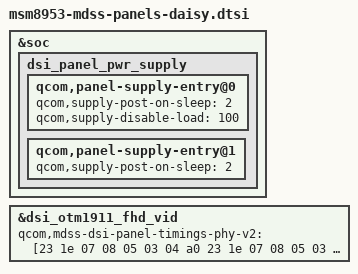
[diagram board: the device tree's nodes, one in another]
/* Copyright (c) 2015-2017, The Linux Foundation. All rights reserved.
 * Copyright (C) 2018 XiaoMi, Inc.
 *
 * This program is free software; you can redistribute it and/or modify
 * it under the terms of the GNU General Public License version 2 and
 * only version 2 as published by the Free Software Foundation.
 *
 * This program is distributed in the hope that it will be useful,
 * but WITHOUT ANY WARRANTY; without even the implied warranty of
 * MERCHANTABILITY or FITNESS FOR A PARTICULAR PURPOSE.  See the
 * GNU General Public License for more details.
 */

#include "dsi-panel-otm1911-fhd-video.dtsi"
#include "dsi-panel-otm1911-fhdplus-video.dtsi"
#include "dsi-panel-ili7807-fhdplus-video.dtsi"
#include "dsi-panel-hx8399c-fhdplus-video.dtsi"

&soc {
	dsi_panel_pwr_supply: dsi_panel_pwr_supply {
		qcom,panel-supply-entry@0 {
			qcom,supply-post-on-sleep= <2>;
			qcom,supply-disable-load = <100>;
		};

		qcom,panel-supply-entry@1 {
			qcom,supply-post-on-sleep= <2>;
		};
	};
};

&dsi_otm1911_fhd_vid {
	qcom,mdss-dsi-panel-timings-phy-v2 = [23 1e 07 08 05 03 04 a0
		23 1e 07 08 05 03 04 a0
		23 1e 07 08 05 03 04 a0
		23 1e 07 08 05 03 04 a0
		23 18 07 08 05 03 04 a0];
};
